# STM32L151xB register map
File version: 1.0
Registers are 32-bit, read-write, reset 0x0 unless marked. A register's access mark holds for its fields unless they carry their own. Offsets are from the block's base; [hi:lo] are bit positions; {n}, {i} and the like mark numbered series; 'fields as' and 'values as' point back to an identical list.

## TIM6 — TIM
Base 0x40001000
Same registers: TIM7 0x40001400
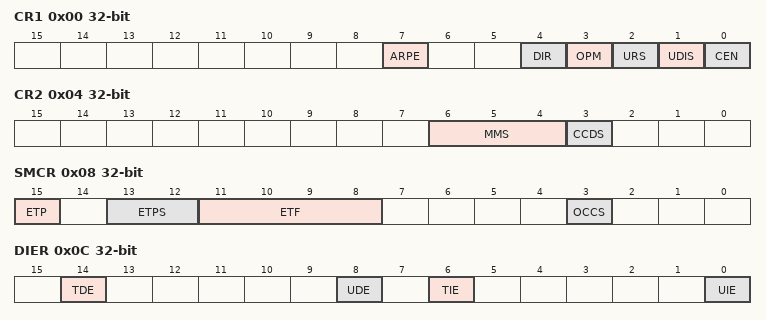
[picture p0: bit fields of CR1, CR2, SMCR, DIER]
0x00 CR1 — TIM control register 1
  [7] ARPE — Auto-reload preload enable
  [4] DIR — Direction
    0=UP (Timer counter counts up); 1=DOWN (Timer counter counts down)
  [3] OPM — One pulse mode
    1=SINGLE (Counter stops counting at the next update event); 0=REPETITIVE (Counter is not stopped at update event)
  [2] URS — Update request source
    0=REGULAR (Counter overflow/underflow, Setting the UG bit or Update generation through the slave mode controller generates an update request); 1=COUNTER (Only counter overflow/underflow generates an update request)
  [1] UDIS — Update disable
  [0] CEN — Counter enable
0x04 CR2 — TIM control register 2
  [6:4] MMS — MMS[2:0] bits (Master Mode Selection)
    0=RESET (UG bit from the TIMx_EGR register is used as trigger output); 1=ENABLE (Counter Enable signal (CNT_EN) is used as trigger output); 2=UPDATE (Update event is used as trigger output); 3=CC1IF (CC1 capture or a compare match is used as trigger output); {v}=OC{v-3}REF (OC{v-3}REF signal is used as trigger output) (v=4..7)
  [3] CCDS — Capture/Compare DMA Selection
    0=CC (CCx DMA request sent when CCx event occurs); 1=UPDATE (CCx DMA requests sent when update event occurs)
0x08 SMCR — TIM slave Mode Control register
  [15] ETP — External trigger polarity
  [13:12] ETPS — ETPS[1:0] bits (External trigger prescaler)
  [11:8] ETF — ETF[3:0] bits (External trigger filter)
  [3] OCCS — OCREF clear selection
    0=OCREF_CLR (OCREF_CLR_INT is connected to the OCREF_CLR input); 1=ETR (OCREF_CLR_INT is connected to ETRF)
0x0C DIER — TIM DMA/interrupt enable register
  [14] TDE — Trigger DMA request enable
  [8] UDE — Update DMA request enable
  [6] TIE — Trigger interrupt enable
  [0] UIE — Update interrupt enable
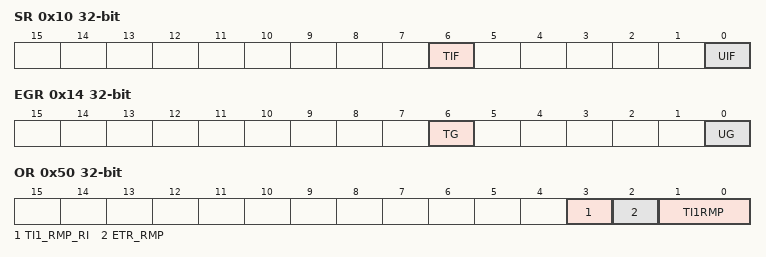
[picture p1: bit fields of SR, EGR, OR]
0x10 SR — TIM status register
  [6] TIF — Trigger interrupt Flag
  [0] UIF — Update interrupt Flag
0x14 EGR — TIM event generation register
  [6] TG — Trigger Generation
  [0] UG — Update Generation
0x24 CNT — TIM counter register
  [15:0] CNT — Counter Value
0x28 PSC — TIM prescaler register
  [15:0] PSC — Prescaler Value
0x2C ARR — TIM auto-reload register
  [15:0] ARR — actual auto-reload Value
0x4C DMAR — TIM DMA address for full transfer
  [15:0] DMAB — DMA register for burst accesses
0x50 OR — TIM option register
  [3] TI1_RMP_RI — TI1_RMP_RI bit (TIM10/11 Input 1 remap for Routing interface)
  [2] ETR_RMP — ETR_RMP bit (TIM10/11 ETR remap)
  [1:0] TI1RMP — TI1_RMP[1:0] bits (TIM Input 1 remap)

## RTC — Real-Time Clock
Base 0x40002800
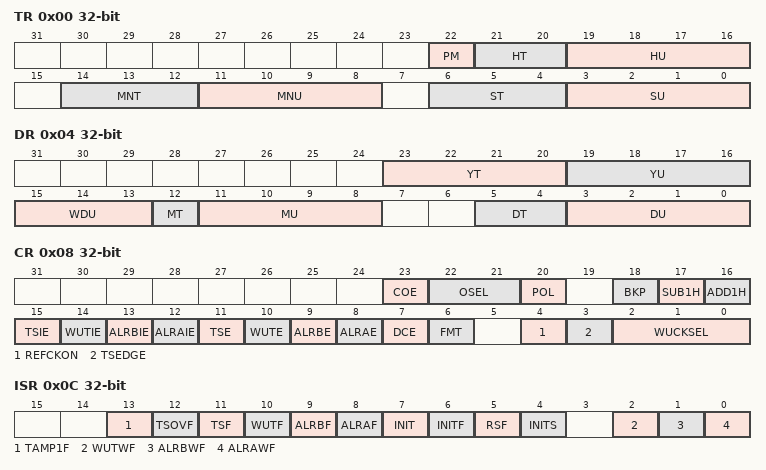
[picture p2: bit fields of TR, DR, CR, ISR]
0x00 TR — RTC time register
  [22] PM
    0=AM_OR_24 (AM or 24-hour format); 1=PM
  [21:20] HT
  [19:16] HU
  [14:12] MNT
  [11:8] MNU
  [6:4] ST
  [3:0] SU
0x04 DR — RTC date register
  [23:20] YT, [19:16] YU, [15:13] WDU, [12] MT, [11:8] MU, [5:4] DT, [3:0] DU
0x08 CR — RTC control register
  [23] COE
  [22:21] OSEL
    0=DISABLE (Output disabled); 1=ALMA (Alarm A output enabled); 2=ALMB (Alarm B output enabled); 3=WAKEUP (Wakeup output enabled)
  [20] POL
    0=HIGH (Pin is high when ALRAF/ALRBF/WUTF is asserted (depending on OSEL)); 1=LOW (Pin is low when ALRAF/ALRBF/WUTF is asserted (depending on OSEL))
  [18] BKP
  [17] SUB1H
  [16] ADD1H
  [15] TSIE
  [14] WUTIE
  [13] ALRBIE
  [12] ALRAIE
  [11] TSE
  [10] WUTE
  [9] ALRBE
  [8] ALRAE
  [7] DCE
  [6] FMT
    0=HOURFORMAT_24HOUR (24 hour/day format); 1=AMPM (AM/PM hour format)
  [4] REFCKON
  [3] TSEDGE
    0=RISING (RTC_TS input rising edge generates a time-stamp event); 1=FALLING (RTC_TS input falling edge generates a time-stamp event)
  [2:0] WUCKSEL
    0=DIV_16 (RTC/16 clock is selected); 1=DIV_8 (RTC/8 clock is selected); 2=DIV_4 (RTC/4 clock is selected); 3=DIV_2 (RTC/2 clock is selected); 4=CKSPRE (ck_spre (usually 1 Hz) clock is selected); 6=CKSPRE_WUT (ck_spre (usually 1 Hz) clock is selected and 2exp16 is added to the WUT counter value)
0x0C ISR — RTC initialization and status register
  [13] TAMP1F, [12] TSOVF, [11] TSF, [10] WUTF, [9] ALRBF, [8] ALRAF, [7] INIT, [6] INITF, [5] RSF, [4] INITS, [2] WUTWF, [1] ALRBWF, [0] ALRAWF
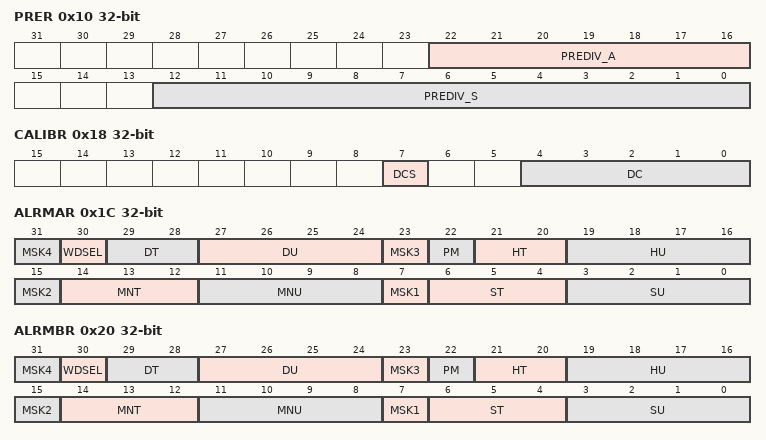
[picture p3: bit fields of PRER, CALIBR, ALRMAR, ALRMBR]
0x10 PRER — RTC prescaler register
  [22:16] PREDIV_A, [12:0] PREDIV_S
0x14 WUTR — RTC wakeup timer register
  [15:0] WUT
0x18 CALIBR — RTC calibration register
  [7] DCS
    0=POSITIVE (Positive calibration: calendar update frequency is increased); 1=NEGATIVE (Negative calibration: calendar update frequency is decreased)
  [4:0] DC
0x1C ALRMAR — RTC alarm A register
  [8n-1] MSK{n} (n=1..4)
  [30] WDSEL
  [29:28] DT
  [27:24] DU
  [22] PM
    0=AM (AM or 24-hour format); 1=PM
  [21:20] HT
  [19:16] HU
  [14:12] MNT
  [11:8] MNU
  [6:4] ST
  [3:0] SU
0x20 ALRMBR — RTC alarm B register
  fields as ALRMAR
0x24 WPR — RTC write protection register
  [7:0] KEY
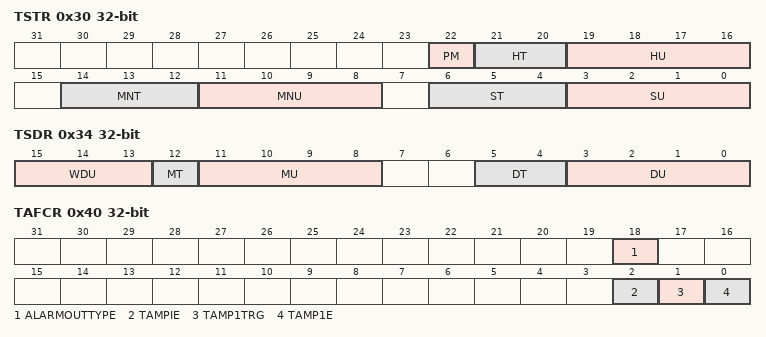
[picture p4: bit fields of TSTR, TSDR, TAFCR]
0x30 TSTR — RTC time stamp time register
  [22] PM
    0=AM (AM or 24-hour format); 1=PM
  [21:20] HT
  [19:16] HU
  [14:12] MNT
  [11:8] MNU
  [6:4] ST
  [3:0] SU
0x34 TSDR — RTC time stamp date register
  [15:13] WDU, [12] MT, [11:8] MU, [5:4] DT, [3:0] DU
0x40 TAFCR — RTC tamper and alternate function configuration register
  [18] ALARMOUTTYPE
    0=OPENDRAIN (RTC_ALARM, when mapped on PC13, is open-drain output); 1=PUSHPULL (RTC_ALARM, when mapped on PC13, is push-pull output)
  [2] TAMPIE
  [1] TAMP1TRG
  [0] TAMP1E
{0x50+4i} BKP{i}R (i=0..19) — RTC backup register {i}
